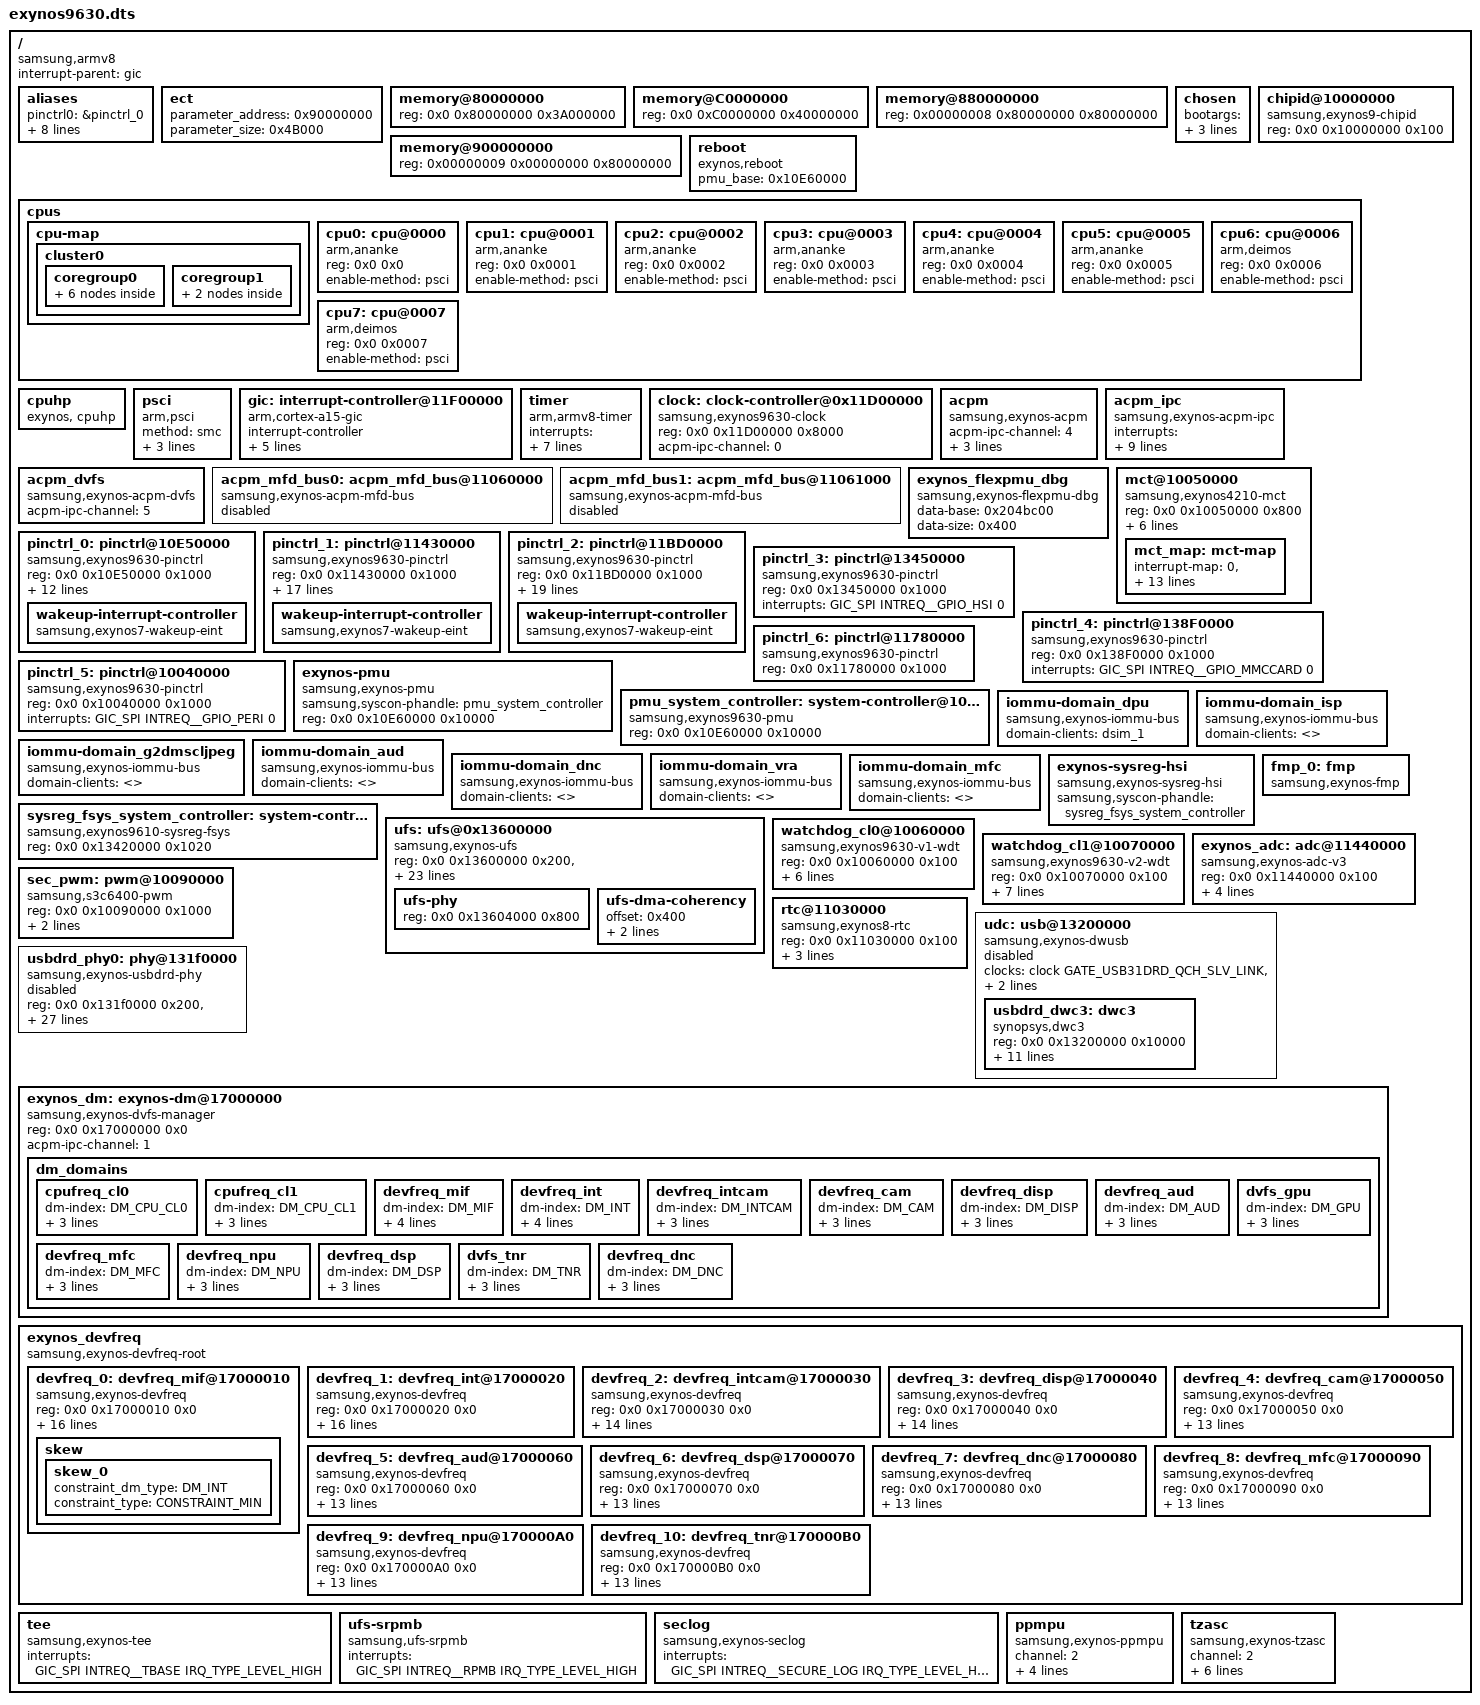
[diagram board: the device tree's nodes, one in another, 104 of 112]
/*
 * SAMSUNG EXYNOS9630 SoC device tree source
 *
 * Copyright (c) 2019 Samsung Electronics Co., Ltd.
 *		http://www.samsung.com
 *
 * SAMSUNG EXYNOS9630 SoC device nodes are listed in this file.
 * EXYNOS9630 based board files can include this file and provide
 * values for board specfic bindings.
 *
 * This program is free software; you can redistribute it and/or modify
 * it under the terms of the GNU General Public License version 2 as
 * published by the Free Software Foundation.
 */

/dts-v1/;
#include <dt-bindings/interrupt-controller/arm-gic.h>
#include <dt-bindings/interrupt-controller/exynos9630.h>
#include <dt-bindings/clock/exynos9630.h>
#include "exynos9630-pinctrl.dtsi"
#include "exynos9630-usi.dtsi"
#include "exynos9630-rmem.dtsi"
#include "exynos9630-dpu.dtsi"
#include "exynos9630-sysmmu.dtsi"
#include <dt-bindings/ufs/ufs.h>
#include "exynos9630-mali.dtsi"
#include <dt-bindings/soc/samsung/exynos9630-dm.h>
#include <dt-bindings/soc/samsung/exynos9630-devfreq.h>
#include "exynos9630-pm-domains.dtsi"

/ {
	compatible = "samsung,armv8", "samsung,exynos9630";
	interrupt-parent = <&gic>;
	#address-cells = <2>;
	#size-cells = <1>;

	aliases {
		pinctrl0 = &pinctrl_0;
		pinctrl1 = &pinctrl_1;
		pinctrl2 = &pinctrl_2;
		pinctrl3 = &pinctrl_3;
		pinctrl4 = &pinctrl_4;
		pinctrl5 = &pinctrl_5;
		pinctrl6 = &pinctrl_6;
		uart0 = &serial_0;
		fmp0 = &fmp_0;
	};

	ect {
		parameter_address = <0x90000000>;
		parameter_size = <0x4B000>;
	};

	memory@80000000 {
		device_type = "memory";
		reg = <0x0 0x80000000 0x3A000000>;
	};

	memory@C0000000 {
		device_type = "memory";
		reg = <0x0 0xC0000000 0x40000000>;
	};

	memory@880000000 {
		device_type = "memory";
		reg = <0x00000008 0x80000000 0x80000000>;
	};

	memory@900000000 {
		device_type = "memory";
		reg = <0x00000009 0x00000000 0x80000000>;
	};

	chosen: chosen {
		bootargs = "earlycon=exynos4210,0x13800000 console=ttySAC0,115200n8 skip_initramfs rootwait ro init=/init root=/dev/sda12 clk_ignore_unused androidboot.hardware=exynos9630 androidboot.selinux=enforce androidboot.debug_level=0x4948 firmware_class.path=/vendor/firmware";
		linux,initrd-start = <0x84000000>;
		linux,initrd-end = <0x841FFFFF>;
	};

	chipid@10000000 {
		compatible = "samsung,exynos9-chipid";
		reg = <0x0 0x10000000 0x100>;
	};

	reboot {
		compatible = "exynos,reboot";
		pmu_base = <0x10E60000>;
	};

	cpus {
		#address-cells = <2>;
		#size-cells = <0>;

		cpu-map {
			cluster0 {
				coregroup0 {
					core0 {
						cpu = <&cpu0>;
					};
					core1 {
						cpu = <&cpu1>;
					};
					core2 {
						cpu = <&cpu2>;
					};
					core3 {
						cpu = <&cpu3>;
					};
					core4 {
						cpu = <&cpu4>;
					};
					core5 {
						cpu = <&cpu5>;
					};
				};
				coregroup1 {
					core0 {
						cpu = <&cpu6>;
					};
					core1 {
						cpu = <&cpu7>;
					};
				};
			};
		};

		cpu0: cpu@0000 {
			device_type = "cpu";
			compatible = "arm,ananke", "arm,armv8";
			reg = <0x0 0x0>;
			enable-method = "psci";
		};
		cpu1: cpu@0001 {
			device_type = "cpu";
			compatible = "arm,ananke", "arm,armv8";
			reg = <0x0 0x0001>;
			enable-method = "psci";
		};
		cpu2: cpu@0002 {
			device_type = "cpu";
			compatible = "arm,ananke", "arm,armv8";
			reg = <0x0 0x0002>;
			enable-method = "psci";
		};
		cpu3: cpu@0003 {
			device_type = "cpu";
			compatible = "arm,ananke", "arm,armv8";
			reg = <0x0 0x0003>;
			enable-method = "psci";
		};
		cpu4: cpu@0004 {
			device_type = "cpu";
			compatible = "arm,ananke", "arm,armv8";
			reg = <0x0 0x0004>;
			enable-method = "psci";
		};
		cpu5: cpu@0005 {
			device_type = "cpu";
			compatible = "arm,ananke", "arm,armv8";
			reg = <0x0 0x0005>;
			enable-method = "psci";
		};
		cpu6: cpu@0006 {
			device_type = "cpu";
			compatible = "arm,deimos", "arm,armv8";
			reg = <0x0 0x0006>;
			enable-method = "psci";
		};
		cpu7: cpu@0007 {
			device_type = "cpu";
			compatible = "arm,deimos", "arm,armv8";
			reg = <0x0 0x0007>;
			enable-method = "psci";
		};
	};

	cpuhp {
		compatible = "exynos, cpuhp";
	};

	psci {
		compatible = "arm,psci";
		method = "smc";
		cpu_suspend = <0xC4000001>;
		cpu_off = <0x84000002>;
		cpu_on = <0xC4000003>;
	};

	gic:interrupt-controller@11F00000 {
		compatible = "arm,cortex-a15-gic", "arm,cortex-a9-gic";
		#interrupt-cells = <3>;
		#address-cells = <0>;
		interrupt-controller;
		reg =	<0x0 0x11F01000 0x1000>,
			<0x0 0x11F02000 0x1000>,
			<0x0 0x11F04000 0x2000>,
			<0x0 0x11F06000 0x2000>;
		interrupts = <GIC_PPI 9 (GIC_CPU_MASK_SIMPLE(4) | IRQ_TYPE_LEVEL_HIGH)>;
	};

	timer {
		compatible = "arm,armv8-timer";
		interrupts = <GIC_PPI 13
				(GIC_CPU_MASK_SIMPLE(8) | IRQ_TYPE_LEVEL_LOW)>,
			     <GIC_PPI 14
				(GIC_CPU_MASK_SIMPLE(8) | IRQ_TYPE_LEVEL_LOW)>,
			     <GIC_PPI 11
				(GIC_CPU_MASK_SIMPLE(8) | IRQ_TYPE_LEVEL_LOW)>,
			     <GIC_PPI 10
				(GIC_CPU_MASK_SIMPLE(8) | IRQ_TYPE_LEVEL_LOW)>;
	        clock-frequency = <26000000>;
		use-clocksource-only;
		use-physical-timer;
	};

	clock: clock-controller@0x11D00000 {
		compatible = "samsung,exynos9630-clock";
		reg = <0x0 0x11D00000 0x8000>;
		#clock-cells = <1>;
		acpm-ipc-channel = <0>;
	};

	acpm {
		compatible = "samsung,exynos-acpm";
		#address-cells = <2>;
		#size-cells = <1>;
		acpm-ipc-channel = <4>;
		fvmap_offset = <0xCC00>;
		reg = <0x0 0x10E30000 0x1000>;		/* TIMER_APM */
		reg-names = "timer_apm";
		peritimer-cnt = <0xFFFF>;
	};

	acpm_ipc {
		compatible = "samsung,exynos-acpm-ipc";
		#address-cells = <2>;
		#size-cells = <1>;
		interrupts = <GIC_SPI INTREQ__MAILBOX_APM2AP IRQ_TYPE_LEVEL_HIGH>;	/* AP2APM MAILBOX SPI NUM*/
		reg = <0x0 0x10F00000 0x1000>,		/* AP2APM MAILBOX */
			<0x0 0x2039000 0x30000>;	/* APM SRAM */
		initdata-base = <0x7000>;
		num-timestamps = <32>;
		debug-log-level = <0>;
		logging-period = <500>;
		dump-base = <0x204F800>;
		dump-size = <0x2D000>;			/* 180KB */
	};

	acpm_dvfs {
		compatible = "samsung,exynos-acpm-dvfs";
		acpm-ipc-channel = <5>;
	};

	acpm_mfd_bus0: acpm_mfd_bus@11060000 {
		compatible = "samsung,exynos-acpm-mfd-bus";
		status = "disabled";
	};

	acpm_mfd_bus1: acpm_mfd_bus@11061000 {
		compatible = "samsung,exynos-acpm-mfd-bus";
		status = "disabled";
	};

	exynos_flexpmu_dbg {
		compatible = "samsung,exynos-flexpmu-dbg";
		#address-cells = <2>;
		#size-cells = <1>;
		data-base = <0x204bc00>;
		data-size = <0x400>;
	};

	mct@10050000 {
		compatible = "samsung,exynos4210-mct";
		reg = <0x0 0x10050000 0x800>;
		interrupt-controller;
		#interrupt-cells = <1>;
		interrupt-parent = <&mct_map>;
		interrupts =	<0>, <1>, <2>, <3>,
				<4>, <5>, <6>, <7>,
				<8>, <9>, <10>, <11>;
		clocks = <&clock OSCCLK>, <&clock GATE_MCT_QCH>;
		clock-names = "fin_pll", "mct";
		use-clockevent-only;

		mct_map: mct-map {
			#interrupt-cells = <1>;
			#address-cells = <0>;
			#size-cells = <0>;
			interrupt-map = <0 &gic 0 INTREQ__MCT_G0 IRQ_TYPE_LEVEL_HIGH>,
					<1 &gic 0 INTREQ__MCT_G1 IRQ_TYPE_LEVEL_HIGH>,
					<2 &gic 0 INTREQ__MCT_G2 IRQ_TYPE_LEVEL_HIGH>,
					<3 &gic 0 INTREQ__MCT_G3 IRQ_TYPE_LEVEL_HIGH>,
					<4 &gic 0 INTREQ__MCT_L0 IRQ_TYPE_LEVEL_HIGH>,
					<5 &gic 0 INTREQ__MCT_L1 IRQ_TYPE_LEVEL_HIGH>,
					<6 &gic 0 INTREQ__MCT_L2 IRQ_TYPE_LEVEL_HIGH>,
					<7 &gic 0 INTREQ__MCT_L3 IRQ_TYPE_LEVEL_HIGH>,
					<8 &gic 0 INTREQ__MCT_L4 IRQ_TYPE_LEVEL_HIGH>,
					<9 &gic 0 INTREQ__MCT_L5 IRQ_TYPE_LEVEL_HIGH>,
					<10 &gic 0 INTREQ__MCT_L6 IRQ_TYPE_LEVEL_HIGH>,
					<11 &gic 0 INTREQ__MCT_L7 IRQ_TYPE_LEVEL_HIGH>;
		};
	};

	/* ALIVE */
	pinctrl_0: pinctrl@10E50000 {
		compatible = "samsung,exynos9630-pinctrl";
		reg = <0x0 0x10E50000 0x1000>;
		interrupts = <GIC_SPI INTREQ__ALIVE_EINT0 0>,
			     <GIC_SPI INTREQ__ALIVE_EINT1 0>,
			     <GIC_SPI INTREQ__ALIVE_EINT2 0>,
			     <GIC_SPI INTREQ__ALIVE_EINT3 0>,
			     <GIC_SPI INTREQ__ALIVE_EINT4 0>,
			     <GIC_SPI INTREQ__ALIVE_EINT5 0>,
			     <GIC_SPI INTREQ__ALIVE_EINT6 0>,
			     <GIC_SPI INTREQ__ALIVE_EINT7 0>,
			     <GIC_SPI INTREQ__ALIVE_EINT8 0>,
			     <GIC_SPI INTREQ__ALIVE_EINT9 0>,
			     <GIC_SPI INTREQ__ALIVE_EINT10 0>,
			     <GIC_SPI INTREQ__ALIVE_EINT11 0>;

		wakeup-interrupt-controller {
			compatible = "samsung,exynos7-wakeup-eint";
		};
	};

	/* CMGP */
	pinctrl_1: pinctrl@11430000 {
		compatible = "samsung,exynos9630-pinctrl";
		reg = <0x0 0x11430000 0x1000>;
		interrupts = <GIC_SPI INTREQ__EXT_INTM00 IRQ_TYPE_LEVEL_HIGH>,
			     <GIC_SPI INTREQ__EXT_INTM01 IRQ_TYPE_LEVEL_HIGH>,
			     <GIC_SPI INTREQ__EXT_INTM02 IRQ_TYPE_LEVEL_HIGH>,
			     <GIC_SPI INTREQ__EXT_INTM03 IRQ_TYPE_LEVEL_HIGH>,
			     <GIC_SPI INTREQ__EXT_INTM04 IRQ_TYPE_LEVEL_HIGH>,
			     <GIC_SPI INTREQ__EXT_INTM05 IRQ_TYPE_LEVEL_HIGH>,
			     <GIC_SPI INTREQ__EXT_INTM06 IRQ_TYPE_LEVEL_HIGH>,
			     <GIC_SPI INTREQ__EXT_INTM07 IRQ_TYPE_LEVEL_HIGH>,
			     <GIC_SPI INTREQ__EXT_INTM08 IRQ_TYPE_LEVEL_HIGH>,
			     <GIC_SPI INTREQ__EXT_INTM09 IRQ_TYPE_LEVEL_HIGH>,
			     <GIC_SPI INTREQ__EXT_INTM10 IRQ_TYPE_LEVEL_HIGH>,
			     <GIC_SPI INTREQ__EXT_INTM11 IRQ_TYPE_LEVEL_HIGH>,
			     <GIC_SPI INTREQ__EXT_INTM12 IRQ_TYPE_LEVEL_HIGH>,
			     <GIC_SPI INTREQ__EXT_INTM13 IRQ_TYPE_LEVEL_HIGH>,
			     <GIC_SPI INTREQ__EXT_INTM14 IRQ_TYPE_LEVEL_HIGH>,
			     <GIC_SPI INTREQ__EXT_INTM15 IRQ_TYPE_LEVEL_HIGH>;

		wakeup-interrupt-controller {
			compatible = "samsung,exynos7-wakeup-eint";
		};
	};

	/* CHUB */
	pinctrl_2: pinctrl@11BD0000 {
		compatible = "samsung,exynos9630-pinctrl";
		reg = <0x0 0x11BD0000 0x1000>;
		interrupts = <GIC_SPI INTREQ__EXT_INTH0_0 IRQ_TYPE_LEVEL_HIGH>,
			     <GIC_SPI INTREQ__EXT_INTH0_1 IRQ_TYPE_LEVEL_HIGH>,
			     <GIC_SPI INTREQ__EXT_INTH0_2 IRQ_TYPE_LEVEL_HIGH>,
			     <GIC_SPI INTREQ__EXT_INTH0_3 IRQ_TYPE_LEVEL_HIGH>,
			     <GIC_SPI INTREQ__EXT_INTH0_4 IRQ_TYPE_LEVEL_HIGH>,
			     <GIC_SPI INTREQ__EXT_INTH0_5 IRQ_TYPE_LEVEL_HIGH>,
			     <GIC_SPI INTREQ__EXT_INTH0_6 IRQ_TYPE_LEVEL_HIGH>,
			     <GIC_SPI INTREQ__EXT_INTH0_7 IRQ_TYPE_LEVEL_HIGH>,
			     <GIC_SPI INTREQ__EXT_INTH1_0 IRQ_TYPE_LEVEL_HIGH>,
			     <GIC_SPI INTREQ__EXT_INTH1_1 IRQ_TYPE_LEVEL_HIGH>,
			     <GIC_SPI INTREQ__EXT_INTH1_2 IRQ_TYPE_LEVEL_HIGH>,
			     <GIC_SPI INTREQ__EXT_INTH1_3 IRQ_TYPE_LEVEL_HIGH>,
			     <GIC_SPI INTREQ__EXT_INTH2_0 IRQ_TYPE_LEVEL_HIGH>,
			     <GIC_SPI INTREQ__EXT_INTH2_1 IRQ_TYPE_LEVEL_HIGH>,
			     <GIC_SPI INTREQ__EXT_INTH2_2 IRQ_TYPE_LEVEL_HIGH>,
			     <GIC_SPI INTREQ__EXT_INTH2_3 IRQ_TYPE_LEVEL_HIGH>,
			     <GIC_SPI INTREQ__EXT_INTH2_4 IRQ_TYPE_LEVEL_HIGH>,
			     <GIC_SPI INTREQ__EXT_INTH2_5 IRQ_TYPE_LEVEL_HIGH>;

		wakeup-interrupt-controller {
			compatible = "samsung,exynos7-wakeup-eint";
		};
	};

	/* HSI */
	pinctrl_3: pinctrl@13450000 {
		compatible = "samsung,exynos9630-pinctrl";
		reg = <0x0 0x13450000 0x1000>;
		interrupts = <GIC_SPI INTREQ__GPIO_HSI 0>;
	};

	/* MMCCARD */
	pinctrl_4: pinctrl@138F0000{
		compatible = "samsung,exynos9630-pinctrl";
		reg = <0x0 0x138F0000 0x1000>;
		interrupts = <GIC_SPI INTREQ__GPIO_MMCCARD 0>;
	};

	/* PERI */
	pinctrl_5: pinctrl@10040000 {
		compatible = "samsung,exynos9630-pinctrl";
		reg = <0x0 0x10040000 0x1000>;
		interrupts = <GIC_SPI INTREQ__GPIO_PERI 0>;
	};

	/* VTS */
	pinctrl_6: pinctrl@11780000 {
		compatible = "samsung,exynos9630-pinctrl";
		reg = <0x0 0x11780000 0x1000>;
	};

	exynos-pmu {
		compatible = "samsung,exynos-pmu";
		samsung,syscon-phandle = <&pmu_system_controller>;
		reg = <0x0 0x10E60000 0x10000>;
		reg-names = "pmu_alive";
	};

	pmu_system_controller: system-controller@10E60000 {
		compatible = "samsung,exynos9630-pmu", "syscon";
		reg = <0x0 0x10E60000 0x10000>;
	};

	iommu-domain_dpu {
		compatible = "samsung,exynos-iommu-bus";
		#dma-address-cells = <2>;
		#dma-size-cells = <1>;
		ranges;

                domain-clients = <&dsim_1>;
	};

	iommu-domain_isp {
		compatible = "samsung,exynos-iommu-bus";
		#dma-address-cells = <2>;
		#dma-size-cells = <1>;
		ranges;

                domain-clients = <>;
	};

	iommu-domain_g2dmscljpeg {
		compatible = "samsung,exynos-iommu-bus";
		#dma-address-cells = <2>;
		#dma-size-cells = <1>;
		ranges;

                domain-clients = <>;
	};

	iommu-domain_aud {
		compatible = "samsung,exynos-iommu-bus";
		#dma-address-cells = <2>;
		#dma-size-cells = <1>;
		ranges;

                domain-clients = <>;
	};

	iommu-domain_dnc {
		compatible = "samsung,exynos-iommu-bus";
		#dma-address-cells = <2>;
		#dma-size-cells = <1>;
		ranges;

                domain-clients = <>;
	};

	iommu-domain_vra {
		compatible = "samsung,exynos-iommu-bus";
		#dma-address-cells = <2>;
		#dma-size-cells = <1>;
		ranges;

                domain-clients = <>;
	};

	iommu-domain_mfc {
		compatible = "samsung,exynos-iommu-bus";
		#dma-address-cells = <2>;
		#dma-size-cells = <1>;
		ranges;

                domain-clients = <>;
	};

	exynos-sysreg-hsi {
		compatible = "samsung,exynos-sysreg-hsi";
		samsung,syscon-phandle = <&sysreg_fsys_system_controller>;
	};

	sysreg_fsys_system_controller: system-controller@13420000 {
		compatible = "samsung,exynos9610-sysreg-fsys", "syscon";
		reg = <0x0 0x13420000 0x1020>;
	};

	fmp_0: fmp {
		compatible = "samsung,exynos-fmp";
	};

	ufs: ufs@0x13600000 {
	     /* ----------------------- */
	     /* 1. SYSTEM CONFIGURATION */
	     /* ----------------------- */
	     compatible ="samsung,exynos-ufs";
	     #address-cells = <2>;
	     #size-cells = <1>;
	     ranges;
	     reg =
		     <0x0 0x13600000 0x200>,	/* 0: HCI standard */
		     <0x0 0x13601100 0x220>,	/* 1: Vendor specificed */
		     <0x0 0x13680000 0xa000>,	/* 2: UNIPRO */
		     <0x0 0x13500000 0x2100>;	/* 3: UFS protector */
	     interrupts = <GIC_SPI INTREQ__UFS_EMBD IRQ_TYPE_LEVEL_HIGH>;
	     pinctrl-names = "default";
	     pinctrl-0 = <&ufs_rst_n &ufs_refclk_out>;
	     clocks =
		     /* aclk clock */
		     <&clock GATE_UFS_EMBD_QCH>,
		     /* unipro clocks */
		     <&clock UFS_EMBD>;

	     clock-names =
		     /* aclk clocks */
		     "GATE_UFS_EMBD_QCH_UFS",
		     /* unipro clocks */
		     "UFS_EMBD";

	     /* PM QoS for INT power domain */
//	     ufs-pm-qos-int = <533000>;

	     /* DMA coherent callback, should be coupled with 'ufs-sys' */
	     dma-coherent;

	     /* UFS PHY isolation and TCXO control */
	     samsung,pmu-phandle = <&pmu_system_controller>;

	     /* TCXO exclusive control  */
	     tcxo-ex-ctrl = <0>;

	     /* UFS IO coherency  */
	     samsung,sysreg-fsys-phandle = <&sysreg_fsys_system_controller>;

	     /* ----------------------- */
	     /* 2. UFS COMMON           */
	     /* ----------------------- */
	     freq-table-hz = <0 0>, <0 0>;

//	     vcc-supply = <&ufs_fixed_vcc>;
//	     vcc-fixed-regulator;
//	     ufs-power-gpio = <&gpa0 0 0>; not used xbootldo
	     ufs-reset-n-gpio = <&gpf0 1 0>;

	     /* ----------------------- */
	     /* 3. UFS EXYNOS           */
	     /* ----------------------- */
	     hw-rev = <UFS_VER_0005>;

	     /* power mode change */
	     ufs,pmd-attr-lane = /bits/ 8 <1>;
	     ufs,pmd-attr-gear = /bits/ 8 <3>;

	     /* hiberantion */
	     ufs-rx-min-activate-time-cap = <3>;
	     ufs-rx-hibern8-time-cap = <2>;
	     ufs-tx-hibern8-time-cap = <2>;

	     /* board type for UFS CAL */
	     brd-for-cal = <0>;

	     fmp-id = <0>;
	     smu-id = <0>;

	     /* ----------------------- */
	     /* 4. ADDITIONAL NODES     */
	     /* ----------------------- */
	     ufs-phy {
		     #address-cells = <2>;
		     #size-cells = <1>;
		     ranges;
		     reg = <0x0 0x13604000 0x800>;
	     };

	     /* SYSREG */
	     ufs-dma-coherency {
		     #address-cells = <2>;
		     #size-cells = <1>;

		     offset = <0x400>;
		     mask = <(BIT_22 | BIT_23)>;
		     val = <(BIT_22 | BIT_23)>;
	     };
	     /*
	      * not confirm this address and can't find cport address
	      ufs-cport {
	      reg =
	      <0x0 0x13108000 0x804>;
	      };
	      */
     };

	watchdog_cl0@10060000 {
		compatible = "samsung,exynos9630-v1-wdt";
		reg = <0x0 0x10060000 0x100>;
		interrupts = <GIC_SPI INTREQ__WDT0 IRQ_TYPE_LEVEL_HIGH>;
		clocks = <&clock OSCCLK>, <&clock GATE_WDT0_QCH>;
		clock-names = "rate_watchdog", "gate_watchdog";
		timeout-sec = <30>;
		samsung,syscon-phandle = <&pmu_system_controller>;
		index = <0>; /* if little cluster then index is 0*/
	};

	watchdog_cl1@10070000 {
		compatible = "samsung,exynos9630-v2-wdt";
		reg = <0x0 0x10070000 0x100>;
		interrupts = <GIC_SPI INTREQ__WDT1 IRQ_TYPE_LEVEL_HIGH>;
		clocks = <&clock OSCCLK>, <&clock GATE_WDT1_QCH>;
		clock-names = "rate_watchdog", "gate_watchdog";
		timeout-sec = <30>;
		samsung,syscon-phandle = <&pmu_system_controller>;
		index = <1>; /* if little cluster then index is 0*/
		use_multistage_wdt; /* Use FIQ debug watchdog */
	};

	exynos_adc: adc@11440000 {
		compatible = "samsung,exynos-adc-v3";
		reg = <0x0 0x11440000 0x100>;
		interrupts = <GIC_SPI INTREQ__ADC_CMGP2AP IRQ_TYPE_LEVEL_HIGH>;
		#io-channel-cells = <1>;
		io-channel-ranges;
		clocks = <&clock GATE_ADC_CMGP_QCH_S0>;
		clock-names = "gate_adcif";
	};

	sec_pwm: pwm@10090000 {
		compatible = "samsung,s3c6400-pwm";
		reg = <0x0 0x10090000 0x1000>;
		samsung,pwm-outputs = <0>, <1>, <2>, <3>, <4>;
		#pwm-cells = <3>;
		clocks = <&clock GATE_PWM_QCH>, <&clock OSCCLK>;
		clock-names = "pwm_pclk", "pwm_sclk";
		status = "ok";
	};

	rtc@11030000 {
		compatible = "samsung,exynos8-rtc";
		reg = <0x0 0x11030000 0x100>;
		interrupts = <GIC_SPI INTREQ__RTC_ALARM_INT IRQ_TYPE_LEVEL_HIGH>,
			     <GIC_SPI INTREQ__RTC_TIC_INT_0 IRQ_TYPE_LEVEL_HIGH>;
	};

	udc: usb@13200000 {
		compatible = "samsung,exynos-dwusb";
		clocks = <&clock GATE_USB31DRD_QCH_SLV_LINK>, <&clock USB31DRD>;
		clock-names = "aclk", "sclk";
		reg = <0x0 0x13200000 0x10000>;
		#address-cells = <2>;
		#size-cells = <1>;
		ranges;
		//samsung,power-domain = <&pd_fsys0a>;
		status = "disabled";

		usbdrd_dwc3: dwc3 {
			compatible = "synopsys,dwc3";
			reg = <0x0 0x13200000 0x10000>;
			interrupts = <0 INTREQ__USB31DRD_GIC_0 0>;
			tx-fifo-resize = <0>;
			adj-sof-accuracy = <0>;
			is_not_vbus_pad = <1>;
			enable_sprs_transfer = <1>;
			phys = <&usbdrd_phy0 0>, <&usbdrd_phy0 1>;
			phy-names = "usb2-phy", "usb3-phy";
			/* check susphy support */
			xhci_l2_support = <0>;
			/* support usb audio offloading: 1, if not: 0 */
			usb_audio_offloading = <0>;
			//abox = <&abox>; /* Temporary block */
			/* support USB L2 sleep */
			 ldos = <3>;
			ldo_number = <10 11 12>;
			/* INT min lock support */
			usb-pm-qos-int = <400000>;
		};
	};

	usbdrd_phy0: phy@131f0000 {
		compatible = "samsung,exynos-usbdrd-phy";
		reg = <0x0 0x131f0000 0x200>,
			<0x0 0x130A0000 0x2800>,
			<0x0 0x130B0000 0x800>;
		interrupts = <0 INTREQ__USB2_REMOTE_WAKEUP_GIC 0>,
			     <0 INTREQ__USB2_REMOTE_CONNECT_GIC 0>;
		clocks = <&clock OSCCLK>, <&clock GATE_USB31DRD_QCH_SLV_LINK>;
		clock-names = "ext_xtal", "aclk";
		samsung,pmu-syscon = <&pmu_system_controller>;
		pmu_mask = <0x0>;
		pmu_offset = <0x72c>;
		pmu_offset_dp = <0x704>;

		/* USBDP combo phy version  - 0x200 */
		phy_version = <0x301>;
		/* if it doesn't need phy user mux, */
		/*  you should write "none" */
		/*  but refclk shouldn't be omitted */
		phyclk_mux = "none";
		phy_refclk = "ext_xtal";

		/* if Main phy has the other phy, it must be set to 1. jusf for usbphy_info */
		has_other_phy = <0>;
		/* if combo phy is used, it must be set to 1. usbphy_sub_info is enabled */
		has_combo_phy = <1>;
		sub_phy_version = <0x400>;

		/* ip type */
		/* USB3DRD = 0 */
		/*  USB3HOST = 1 */
		/*  USB2DRD = 2 */
		/*  USB2HOST = 3 */
		ip_type = <0x0>;

		/* for PHY CAL */
		/* choice only one item */
		phy_refsel_clockcore = <1>;
		phy_refsel_ext_osc = <0>;
		phy_refsel_xtal = <0>;
		phy_refsel_diff_pad = <0>;
		phy_refsel_diff_internal = <0>;
		phy_refsel_diff_single = <0>;

		/* true : 1 , false : 0 */
		use_io_for_ovc = <0>;
		common_block_disable = <1>;
		is_not_vbus_pad = <1>;
		used_phy_port = <0>;

		status = "disabled";

		#phy-cells = <1>;
		ranges;
       };

	exynos_dm: exynos-dm@17000000 {
		compatible = "samsung,exynos-dvfs-manager";
		reg = <0x0 0x17000000 0x0>;
		acpm-ipc-channel = <1>;
		dm_domains {
			cpufreq_cl0 {
				dm-index = <DM_CPU_CL0>;
				available = "true";
				cal_id = <ACPM_DVFS_CPUCL0>;
				dm_type_name = "dm_cpu_cl0";
			};
			cpufreq_cl1 {
				dm-index = <DM_CPU_CL1>;
				available = "true";
				cal_id = <ACPM_DVFS_CPUCL1>;
				dm_type_name = "dm_cpu_cl1";
			};
			devfreq_mif {
				dm-index = <DM_MIF>;
				available = "true";
				policy_use = "true";
				cal_id = <ACPM_DVFS_MIF>;
				dm_type_name = "dm_mif";
			};
			devfreq_int {
				dm-index = <DM_INT>;
				available = "true";
				policy_use = "true";
				cal_id = <ACPM_DVFS_INT>;
				dm_type_name = "dm_int";
			};
			devfreq_intcam {
				dm-index = <DM_INTCAM>;
				available = "true";
				cal_id = <ACPM_DVFS_INTCAM>;
				dm_type_name = "dm_intcam";
			};
			devfreq_cam {
				dm-index = <DM_CAM>;
				available = "true";
				cal_id = <ACPM_DVFS_CAM>;
				dm_type_name = "dm_cam";
			};
			devfreq_disp {
				dm-index = <DM_DISP>;
				available = "true";
				cal_id = <ACPM_DVFS_DISP>;
				dm_type_name = "dm_disp";
			};
			devfreq_aud {
				dm-index = <DM_AUD>;
				available = "true";
				cal_id = <ACPM_DVFS_AUD>;
				dm_type_name = "dm_aud";
			};
			dvfs_gpu {
				dm-index = <DM_GPU>;
				available = "false";
				cal_id = <ACPM_DVFS_G3D>;
				dm_type_name = "dm_gpu";
			};
			devfreq_mfc {
				dm-index = <DM_MFC>;
				available = "true";
				cal_id = <ACPM_DVFS_MFC>;
				dm_type_name = "dm_mfc";
			};
			devfreq_npu {
				dm-index = <DM_NPU>;
				available = "true";
				cal_id = <ACPM_DVFS_NPU>;
				dm_type_name = "dm_npu";
			};
			devfreq_dsp {
				dm-index = <DM_DSP>;
				available = "true";
				cal_id = <ACPM_DVFS_DSP>;
				dm_type_name = "dm_dsp";
			};
			dvfs_tnr {
				dm-index = <DM_TNR>;
				available = "true";
				cal_id = <ACPM_DVFS_TNR>;
				dm_type_name = "dm_tnr";
			};
			devfreq_dnc {
				dm-index = <DM_DNC>;
				available = "true";
				cal_id = <ACPM_DVFS_DNC>;
				dm_type_name = "dm_dnc";
			};
		};
	};

	exynos_devfreq {
		compatible = "samsung,exynos-devfreq-root";
		#address-cells = <2>;
		#size-cells = <1>;
		ranges;
		devfreq_0: devfreq_mif@17000010 {
			compatible = "samsung,exynos-devfreq";
			reg = <0x0 0x17000010 0x0>;
			devfreq_type = <DEVFREQ_MIF>;
			devfreq_domain_name = "MIF";
			pm_qos_class = <DT_PM_QOS_BUS_THROUGHPUT>; /* PM_QOS_BUS_THROUGHPUT */
			pm_qos_class_max = <DT_PM_QOS_BUS_THROUGHPUT_MAX>; /* PM_QOS_BUS_THROUGHPUT_MAX */
			ess_flag = <ESS_FLAG_MIF>;
			dm-index = <DM_MIF>;

			/* Delay time */
			use_delay_time = "false";

			freq_info = <2093000 421000 421000 421000 2093000 421000>;
			/* initial_freq, default_qos, suspend_freq, min_freq, max_freq reboot_freq */

			/* Booting value */
			boot_info = <40 2093000>;
			/* boot_qos_timeout, boot_freq */

			/* governor data */
			governor = <SIMPLE_INTERACTIVE>;

			bts_update = "false";
			dfs_id = <ACPM_DVFS_MIF>;
			acpm-ipc-channel = <1>;
			use_acpm = "true";
			update_fvp = "true";
			skew {
				skew_0 {
					constraint_dm_type = <DM_INT>;
					constraint_type = <CONSTRAINT_MIN>;
				};
			};
		};

		devfreq_1: devfreq_int@17000020 {
			compatible = "samsung,exynos-devfreq";
			reg = <0x0 0x17000020 0x0>;
			devfreq_type = <DEVFREQ_INT>;
			devfreq_domain_name = "INT";
			pm_qos_class = <DT_PM_QOS_DEVICE_THROUGHPUT>; /* PM_QOS_DEVICE_THROUGHPUT */
			pm_qos_class_max = <DT_PM_QOS_DEVICE_THROUGHPUT_MAX>; /* PM_QOS_DEVICE_THROUGHPUT_MAX */
			ess_flag = <ESS_FLAG_INT>;
			dm-index = <DM_INT>;

			/* Delay time */
			use_delay_time = "false";

			freq_info = <666000 133000 133000 133000 666000 133000>;
			/* <initial_freq, default_qos, suspend_freq, min, max, reboot_freq> */

			/* Booting value */
			boot_info = <40 666000>;
			/* boot_qos_timeout, boot_freq */

			/* governor data */
			governor = <SIMPLE_INTERACTIVE>;

			bts_update = "false";
			dfs_id = <ACPM_DVFS_INT>;
			acpm-ipc-channel = <1>;
			use_acpm = "true";
		};

		devfreq_2: devfreq_intcam@17000030 {
			compatible = "samsung,exynos-devfreq";
			reg = <0x0 0x17000030 0x0>;
			devfreq_type = <DEVFREQ_INTCAM>;
			devfreq_domain_name = "INTCAM";
			pm_qos_class = <DT_PM_QOS_INTCAM_THROUGHPUT>; /* PM_QOS_INTCAM_THROUGHPUT */
			pm_qos_class_max = <DT_PM_QOS_INTCAM_THROUGHPUT_MAX>; /* PM_QOS_INTCAM_THROUGHPUT_MAX */
			ess_flag = <ESS_FLAG_INTCAM>;
			dm-index = <DM_INTCAM>;

			/* Delay time */
			use_delay_time = "false";

			freq_info = <533000 107000 107000 107000 533000 107000>;
			/* <initial_freq, default_qos, suspend_freq, min, max, reboot_freq> */

			/* Booting value */
			boot_info = <40 533000>;
			/* boot_qos_timeout, boot_freq */

			/* governor data */
			governor = <SIMPLE_INTERACTIVE>;

			bts_update = "false";
			dfs_id = <ACPM_DVFS_INTCAM>;
		};

		devfreq_3: devfreq_disp@17000040 {
			compatible = "samsung,exynos-devfreq";
			reg = <0x0 0x17000040 0x0>;
			devfreq_type = <DEVFREQ_DISP>;
			devfreq_domain_name = "DISP";
			pm_qos_class = <DT_PM_QOS_DISPLAY_THROUGHPUT>; /* PM_QOS_DISPLAY_THROUGHPUT */
			pm_qos_class_max = <DT_PM_QOS_DISPLAY_THROUGHPUT_MAX>; /* PM_QOS_DISPLAY_THROUGHPUT_MAX */
			ess_flag = <ESS_FLAG_DISP>;
			dm-index = <DM_DISP>;

			/* Delay time */
			use_delay_time = "false";

			freq_info = <533000 400000 80000 80000 533000 400000>;
			/* <initial_freq, default_qos, suspend_freq, min, max, reboot_freq> */

			/* Booting value */
			boot_info = <40 533000>;
			/* boot_qos_timeout, boot_freq */

			/* governor data */
			governor = <SIMPLE_INTERACTIVE>;

			bts_update = "false";
			dfs_id = <ACPM_DVFS_DISP>;
		};

		devfreq_4: devfreq_cam@17000050 {
			compatible = "samsung,exynos-devfreq";
			reg = <0x0 0x17000050 0x0>;
			devfreq_type = <DEVFREQ_CAM>;
			devfreq_domain_name = "CAM";
			pm_qos_class = <DT_PM_QOS_CAM_THROUGHPUT>; /* PM_QOS_CAM_THROUGHPUT */
			pm_qos_class_max = <DT_PM_QOS_CAM_THROUGHPUT_MAX>; /* PM_QOS_CAM_THROUGHPUT_MAX */
			ess_flag = <ESS_FLAG_CAM>;
			dm-index = <DM_CAM>;

			/* Delay time */
			use_delay_time = "false";

			freq_info = <533000 100000 100000 100000 533000 100000>;
			/* <initial, default_qos, suspend_freq, min, max, reboot_freq> */

			/* Booting value */
			boot_info = <40 533000>;
			/* boot_qos_timeout, boot_freq */

			/* governor data */
			governor = <SIMPLE_INTERACTIVE>;

			bts_update = "false";

			dfs_id = <ACPM_DVFS_CAM>;
		};

		devfreq_5: devfreq_aud@17000060 {
			compatible = "samsung,exynos-devfreq";
			reg = <0x0 0x17000060 0x0>;
			devfreq_type = <DEVFREQ_AUD>;
			devfreq_domain_name = "AUD";
			pm_qos_class = <DT_PM_QOS_AUD_THROUGHPUT>; /* PM_QOS_AUD_THROUGHPUT */
			pm_qos_class_max = <DT_PM_QOS_AUD_THROUGHPUT_MAX>; /* PM_QOS_AUD_THROUGHPUT_MAX */
			ess_flag = <ESS_FLAG_AUD>;
			dm-index = <DM_AUD>;

			/* Delay time */
			use_delay_time = "false";

			freq_info = <1180000 295000 295000 295000 1180000 295000>;
			/* <initial, default_qos, suspend_freq, min, max, reboot_freq> */

			/* Booting value */
			boot_info = <40 1180000>;
			/* boot_qos_timeout, boot_freq */

			/* governor data */
			governor = <SIMPLE_INTERACTIVE>;

			bts_update = "false";
			dfs_id = <ACPM_DVFS_AUD>;

//			samsung,power-domain = <&pd_aud>;
//			pd_name = "pd-aud";
		};

		devfreq_6: devfreq_dsp@17000070 {
			compatible = "samsung,exynos-devfreq";
			reg = <0x0 0x17000070 0x0>;
			devfreq_type = <DEVFREQ_DSP>;
			devfreq_domain_name = "DSP";
			pm_qos_class = <DT_PM_QOS_DSP_THROUGHPUT>; /* PM_QOS_DSP_THROUGHPUT */
			pm_qos_class_max = <DT_PM_QOS_DSP_THROUGHPUT_MAX>; /* PM_QOS_DSP_THROUGHPUT_MAX */
			ess_flag = <ESS_FLAG_DSP>;
			dm-index = <DM_DSP>;

			/* Delay time */
			use_delay_time = "false";

			freq_info = <800000 133000 133000 133000 800000 133000>;
			/* <initial, default_qos, suspend_freq, min, max, reboot_freq> */

			/* Booting value */
			boot_info = <40 800000>;
			/* boot_qos_timeout, boot_freq */

			/* governor data */
			governor = <SIMPLE_INTERACTIVE>;

			bts_update = "false";
			dfs_id = <ACPM_DVFS_DSP>;
		};

		devfreq_7: devfreq_dnc@17000080 {
			compatible = "samsung,exynos-devfreq";
			reg = <0x0 0x17000080 0x0>;
			devfreq_type = <DEVFREQ_DNC>;
			devfreq_domain_name = "DNC";
			pm_qos_class = <DT_PM_QOS_DNC_THROUGHPUT>; /* PM_QOS_DNC_THROUGHPUT */
			pm_qos_class_max = <DT_PM_QOS_DNC_THROUGHPUT_MAX>; /* PM_QOS_DNC_THROUGHPUT_MAX */
			ess_flag = <ESS_FLAG_DNC>;
			dm-index = <DM_DNC>;

			/* Delay time */
			use_delay_time = "false";

			freq_info = <800000 133000 133000 133000 800000 133000>;
			/* <initial, default_qos, suspend_freq, min, max, reboot_freq> */

			/* Booting value */
			boot_info = <40 800000>;
			/* boot_qos_timeout, boot_freq */

			/* governor data */
			governor = <SIMPLE_INTERACTIVE>;

			bts_update = "false";
			dfs_id = <ACPM_DVFS_DNC>;
		};

		devfreq_8: devfreq_mfc@17000090 {
			compatible = "samsung,exynos-devfreq";
			reg = <0x0 0x17000090 0x0>;
			devfreq_type = <DEVFREQ_MFC>;
			devfreq_domain_name = "MFC";
			pm_qos_class = <DT_PM_QOS_MFC_THROUGHPUT>; /* PM_QOS_MFC_THROUGHPUT */
			pm_qos_class_max = <DT_PM_QOS_MFC_THROUGHPUT_MAX>; /* PM_QOS_MFC_THROUGHPUT_MAX */
			ess_flag = <ESS_FLAG_MFC>;
			dm-index = <DM_MFC>;

			/* Delay time */
			use_delay_time = "false";

			freq_info = <666000 100000 100000 100000 666000 100000>;
			/* <initial, default_qos, suspend_freq, min, max, reboot_freq> */

			/* Booting value */
			boot_info = <40 666000>;
			/* boot_qos_timeout, boot_freq */

			/* governor data */
			governor = <SIMPLE_INTERACTIVE>;

			bts_update = "false";
			dfs_id = <ACPM_DVFS_MFC>;
		};

		devfreq_9: devfreq_npu@170000A0 {
			compatible = "samsung,exynos-devfreq";
			reg = <0x0 0x170000A0 0x0>;
			devfreq_type = <DEVFREQ_NPU>;
			devfreq_domain_name = "NPU";
			pm_qos_class = <DT_PM_QOS_NPU_THROUGHPUT>; /* PM_QOS_NPU_THROUGHPUT */
			pm_qos_class_max = <DT_PM_QOS_NPU_THROUGHPUT_MAX>; /* PM_QOS_NPU_THROUGHPUT_MAX */
			ess_flag = <ESS_FLAG_NPU>;
			dm-index = <DM_NPU>;

			/* Delay time */
			use_delay_time = "false";

			freq_info = <800000 133000 133000 133000 800000 133000>;
			/* <initial, default_qos, suspend_freq, min, max, reboot_freq> */

			/* Booting value */
			boot_info = <40 800000>;
			/* boot_qos_timeout, boot_freq */

			/* governor data */
			governor = <SIMPLE_INTERACTIVE>;

			bts_update = "false";
			dfs_id = <ACPM_DVFS_NPU>;
		};

		devfreq_10: devfreq_tnr@170000B0 {
			compatible = "samsung,exynos-devfreq";
			reg = <0x0 0x170000B0 0x0>;
			devfreq_type = <DEVFREQ_TNR>;
			devfreq_domain_name = "TNR";
			pm_qos_class = <DT_PM_QOS_TNR_THROUGHPUT>; /* PM_QOS_TNR_THROUGHPUT */
			pm_qos_class_max = <DT_PM_QOS_TNR_THROUGHPUT_MAX>; /* PM_QOS_TNR_THROUGHPUT_MAX */
			ess_flag = <ESS_FLAG_TNR>;
			dm-index = <DM_TNR>;

			/* Delay time */
			use_delay_time = "false";

			freq_info = <533000 107000 107000 107000 533000 107000>;
			/* <initial, default_qos, suspend_freq, min, max, reboot_freq> */

			/* Booting value */
			boot_info = <40 533000>;
			/* boot_qos_timeout, boot_freq */

			/* governor data */
			governor = <SIMPLE_INTERACTIVE>;

			bts_update = "false";
			dfs_id = <ACPM_DVFS_TNR>;
		};
	};

	/* tbase */
        tee {
	        compatible = "samsung,exynos-tee";
		interrupts = <GIC_SPI INTREQ__TBASE IRQ_TYPE_LEVEL_HIGH>;
	};

	/* Secure RPMB */
	ufs-srpmb {
		compatible = "samsung,ufs-srpmb";
		interrupts = <GIC_SPI INTREQ__RPMB IRQ_TYPE_LEVEL_HIGH>;
	};

	/* Secure Log */
	seclog {
		compatible = "samsung,exynos-seclog";
		interrupts = <GIC_SPI INTREQ__SECURE_LOG IRQ_TYPE_LEVEL_HIGH>;
	};

	ppmpu {
		compatible = "samsung,exynos-ppmpu";
		channel = <2>;
		irqcnt = <2>;
		interrupts = <GIC_SPI INTREQ__DMC_INTR_MIF0 IRQ_TYPE_LEVEL_HIGH>,
			     <GIC_SPI INTREQ__DMC_INTR_MIF1 IRQ_TYPE_LEVEL_HIGH>;
	};

	tzasc {
		compatible = "samsung,exynos-tzasc";
		channel = <2>;
		interleaving_shift = <1>;
		tzc_ver = <380>;
		irqcnt = <2>;
		interrupts = <GIC_SPI INTREQ__DMC_INTR_MIF0 IRQ_TYPE_LEVEL_HIGH>,
			     <GIC_SPI INTREQ__DMC_INTR_MIF1 IRQ_TYPE_LEVEL_HIGH>;
	};
};
